# AT32UC3A3128S device description
Architecture: AVR32_UC3; Family: AVR UC3
Registers are 32-bit, read-write, reset 0x0 unless marked. A register's access mark holds for its fields unless they carry their own. Offsets are from the block's base; [hi:lo] are bit positions; {n}, {i} and the like mark numbered series; 'fields as' and 'values as' point back to an identical list.

## PM — Power Manager
Instances: PM 0xffff0c00
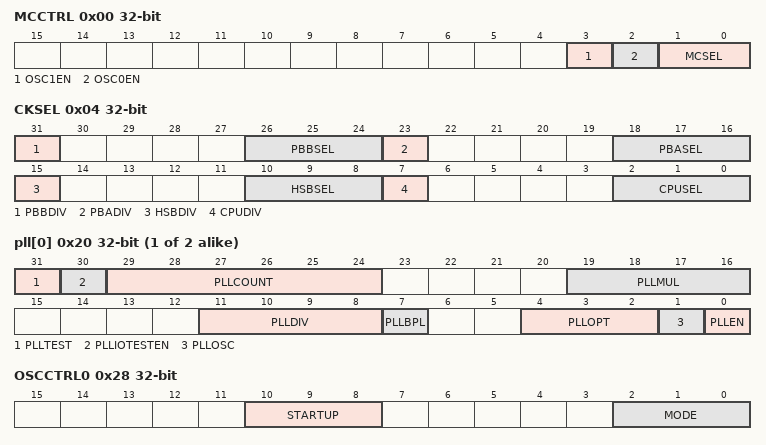
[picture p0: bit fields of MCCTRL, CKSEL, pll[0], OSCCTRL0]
0x00 MCCTRL — Main Clock Control
  [3] OSC1EN — Oscillator 1 Enable
  [2] OSC0EN — Oscillator 0 Enable
  [1:0] MCSEL — Main Clock Select
    0=SLOW; 1=OSC0; 2=PLL0
0x04 CKSEL — Clock Select
  [31] PBBDIV — PBB Division
  [26:24] PBBSEL — PBB Clock Select
  [23] PBADIV — PBA Division
  [18:16] PBASEL — PBA Clock Select
  [15] HSBDIV — HSB Division
  [10:8] HSBSEL — HSB Clock select
  [7] CPUDIV — CPU Division
  [2:0] CPUSEL — CPU Clock Select
0x08 CPUMASK
0x0C HSBMASK
0x10 PBAMASK
0x14 PBBMASK
{0x20+4i} pll[{i}] (i=0..1) access not given
  [31] PLLTEST
  [30] PLLIOTESTEN — PLL IO Test Enable
  [29:24] PLLCOUNT
  [19:16] PLLMUL — PLL Multiply factor
  [11:8] PLLDIV — PLL Division factor
  [7] PLLBPL — PLL Bypass Lock
  [4:2] PLLOPT — PLL Option
  [1] PLLOSC — PLL Oscillator select
  [0] PLLEN — PLL Enable
0x28 OSCCTRL0 — Oscillator 0 Control Register
  [10:8] STARTUP — Oscillator 0 Startup Time
    0=0_RCOSC; 1=64_RCOSC; 2=128_RCOSC; 3=2048_RCOSC; 4=4096_RCOSC; 5=8192_RCOSC; 6=16384_RCOSC
  [2:0] MODE — Oscillator 0 Mode
    0=EXT_CLOCK; {v}=CRYSTAL_G{v-4} (v=4..7)
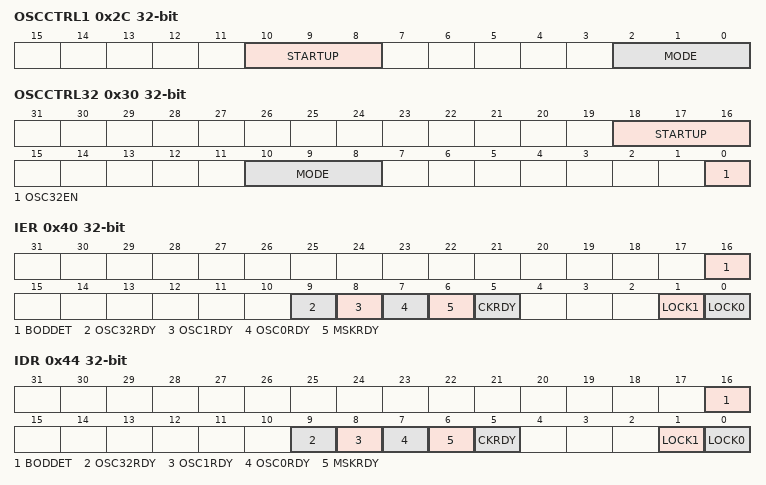
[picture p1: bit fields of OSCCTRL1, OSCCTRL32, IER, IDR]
0x2C OSCCTRL1 — Oscillator 1 Control Register
  [10:8] STARTUP — Oscillator 1 Startup Time
    values as OSCCTRL0.STARTUP
  [2:0] MODE — Oscillator 1 Mode
    0=EXT_CLOCK; {v}=CRYSTAL_G{v-4} (v=4..7)
0x30 OSCCTRL32 — Oscillator 32 Control Register
  [18:16] STARTUP — 32KHz Oscillator Startup Time
    0=0_RCOSC; 1=128_RCOSC; 2=8192_RCOSC; 3=16384_RCOSC; 4=65536_RCOSC; 5=131072_RCOSC; 6=262144_RCOSC; 7=524288_RCOSC
  [10:8] MODE — 32KHz Oscillator Mode
    0=EXT_CLOCK; 1=CRYSTAL
  [0] OSC32EN — Enable the 32KHz oscillator
0x40 IER wo — PM Interrupt Enable Register
  [16] BODDET — Brownout detection
  [9] OSC32RDY — OSC32 ready
  [8] OSC1RDY — OSC1 ready
  [7] OSC0RDY — OSC0 ready
  [6] MSKRDY — Mask ready
  [5] CKRDY — Clock Ready
  [1] LOCK1 — PLL 1 locked
  [0] LOCK0 — PLL 0 locked
0x44 IDR wo — PM Interrupt Disable Register
  fields as IER
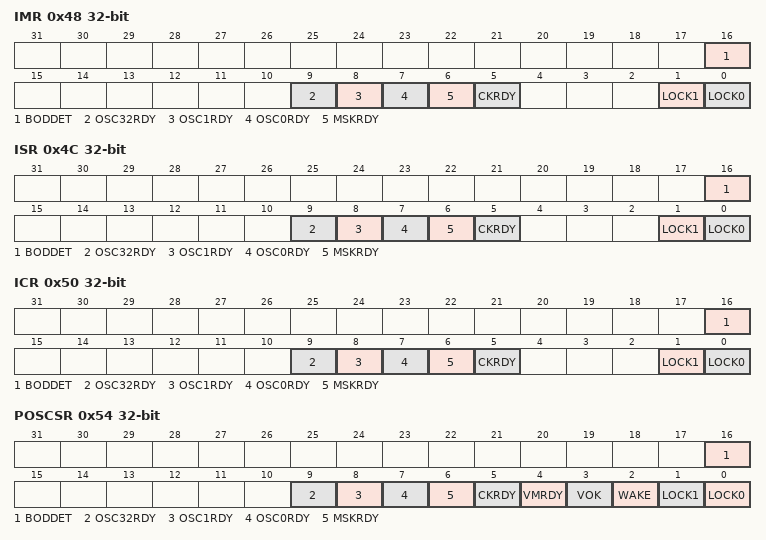
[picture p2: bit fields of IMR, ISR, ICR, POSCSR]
0x48 IMR ro — PM Interrupt Mask Register
  fields as IER
0x4C ISR ro — PM Interrupt Status Register
  fields as IER
0x50 ICR wo — PM Interrupt Clear Register
  [16] BODDET — Brownout detection
  [9] OSC32RDY — OSC32 ready
  [8] OSC1RDY — OSC1 Ready
  [7] OSC0RDY — OSC0 ready
  [6] MSKRDY — Mask ready
  [5] CKRDY — Clock ready
  [1] LOCK1 — PLL 1 locked
  [0] LOCK0 — PLL 0 locked
0x54 POSCSR — Power and Oscillators Status Register
  [16] BODDET — Brownout detection
  [9] OSC32RDY — OSC32 ready
  [8] OSC1RDY — OSC1 ready
  [7] OSC0RDY — OSC0 ready
  [6] MSKRDY — Mask ready
  [5] CKRDY
  [4] VMRDY — Voltage Monitor Ready
  [3] VOK — Voltage OK
  [2] WAKE — Wake pin asserted
  [1] LOCK1 — PLL 1 locked
  [0] LOCK0 — PLL 0 locked
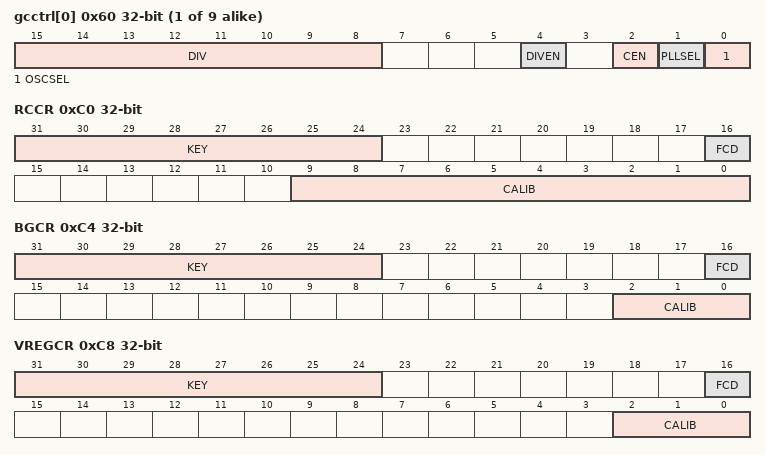
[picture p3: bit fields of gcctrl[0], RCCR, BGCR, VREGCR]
{0x60+4i} gcctrl[{i}] (i=0..8) access not given
  [15:8] DIV — Division Factor
  [4] DIVEN — Divide enable
  [2] CEN — Clock Enable
  [1] PLLSEL — PLL Select
  [0] OSCSEL — Oscillator Select
0xC0 RCCR — RC Oscillator Calibration Register
  [31:24] KEY — Register Write protection
  [16] FCD — Flash Calibration Done
  [9:0] CALIB — Calibration Value
0xC4 BGCR — Bandgap Calibration Register
  [31:24] KEY — Register Write protection
  [16] FCD — Flash Calibration Done
  [2:0] CALIB — Calibration value
0xC8 VREGCR — Buck Regulator Calibration Register
  [31:24] KEY
  [16] FCD — Flash calibration done
  [2:0] CALIB
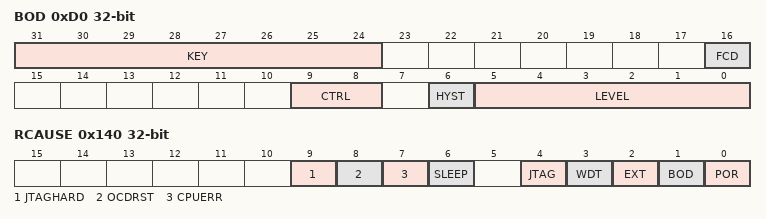
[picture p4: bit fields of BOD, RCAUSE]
0xD0 BOD — BOD Level Register
  [31:24] KEY — Register Write protection
  [16] FCD — BOD Fuse calibration done
  [9:8] CTRL — BOD Control
    0=OFF1; 1=ENABLED; 2=ENABLED_NORESET; 3=OFF2
  [6] HYST — BOD Hysteresis
  [5:0] LEVEL — BOD Level
0x140 RCAUSE ro — Reset Cause
  [9] JTAGHARD — JTAG Hard Reset
  [8] OCDRST — OCD Reset
  [7] CPUERR — CPU Error
  [6] SLEEP
  [4] JTAG — JTAG reset
  [3] WDT — Watchdog Reset
  [2] EXT — External Reset
  [1] BOD — Brown-out Reset
  [0] POR — Power-on Reset
0x144 AWEN — Asynchronous Wake Enable register
  [0] USB_WAKEN — Enable asynchronous wake up by USB attached
{0x200+4i} gplp[{i}] (i=0..1) access not given
